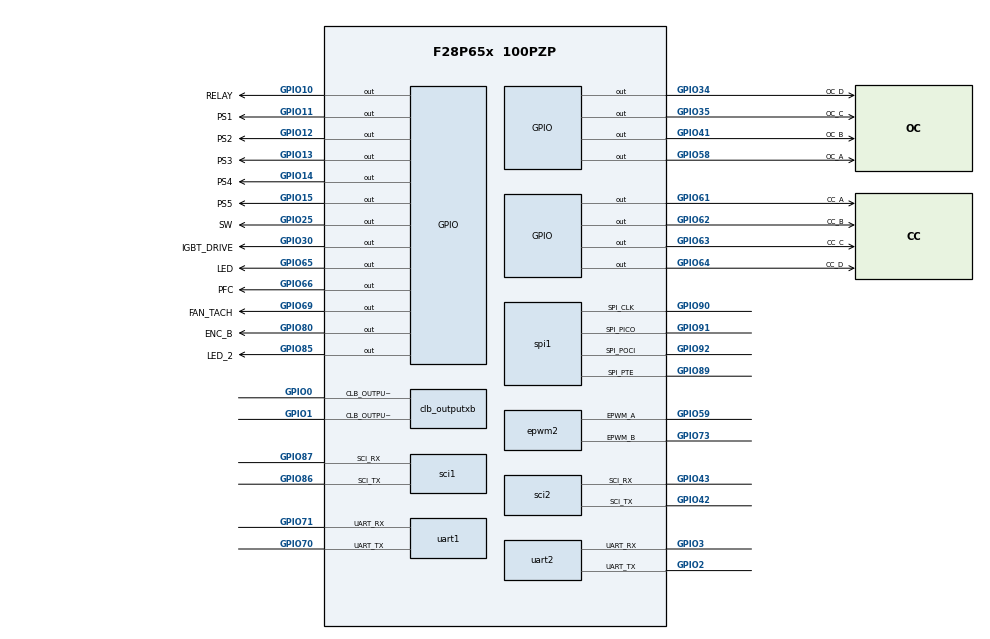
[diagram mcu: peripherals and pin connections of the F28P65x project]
/**
 * @cliArgs --device "F28P65x" --part "F28P65x_100PZP" --package "100PZP" --context "CPU1" --product "C2000WARE@6.00.01.00"
 * @versions {"tool":"1.26.0+4407"}
 */

/**
 * Import the modules used in this configuration.
 */
const adc              = scripting.addModule("/driverlib/adc.js", {}, false);
const adc1             = adc.addInstance();
const adc2             = adc.addInstance();
const adc3             = adc.addInstance();
const asysctl          = scripting.addModule("/driverlib/asysctl.js");
const led              = scripting.addModule("/driverlib/board_components/led", {}, false);
const led1             = led.addInstance();
const led2             = led.addInstance();
const clb              = scripting.addModule("/driverlib/clb.js", {}, false);
const clb1             = clb.addInstance();
const clb_outputxbar   = scripting.addModule("/driverlib/clb_outputxbar.js", {}, false);
const clb_outputxbar1  = clb_outputxbar.addInstance();
const clb_outputxbar2  = clb_outputxbar.addInstance();
const clbxbar          = scripting.addModule("/driverlib/clbxbar.js", {}, false);
const clbxbar1         = clbxbar.addInstance();
const clbxbar2         = clbxbar.addInstance();
const clbxbar3         = clbxbar.addInstance();
const cputimer         = scripting.addModule("/driverlib/cputimer.js", {}, false);
const cputimer1        = cputimer.addInstance();
const dac              = scripting.addModule("/driverlib/dac.js", {}, false);
const dac1             = dac.addInstance();
const dac2             = dac.addInstance();
const epwm             = scripting.addModule("/driverlib/epwm.js", {}, false);
const epwm1            = epwm.addInstance();
const epwm2            = epwm.addInstance();
const epwm3            = epwm.addInstance();
const epwm4            = epwm.addInstance();
const gpio             = scripting.addModule("/driverlib/gpio.js", {}, false);
const gpio3            = gpio.addInstance();
const gpio4            = gpio.addInstance();
const gpio5            = gpio.addInstance();
const gpio6            = gpio.addInstance();
const gpio7            = gpio.addInstance();
const gpio8            = gpio.addInstance();
const gpio9            = gpio.addInstance();
const gpio10           = gpio.addInstance();
const gpio11           = gpio.addInstance();
const gpio12           = gpio.addInstance();
const gpio13           = gpio.addInstance();
const gpio14           = gpio.addInstance();
const gpio15           = gpio.addInstance();
const gpio16           = gpio.addInstance();
const gpio17           = gpio.addInstance();
const gpio18           = gpio.addInstance();
const gpio19           = gpio.addInstance();
const gpio20           = gpio.addInstance();
const gpio21           = gpio.addInstance();
const gpio22           = gpio.addInstance();
const inputxbar_input  = scripting.addModule("/driverlib/inputxbar_input.js", {}, false);
const inputxbar_input1 = inputxbar_input.addInstance();
const inputxbar_input2 = inputxbar_input.addInstance();
const inputxbar_input3 = inputxbar_input.addInstance();
const inputxbar_input4 = inputxbar_input.addInstance();
const inputxbar_input5 = inputxbar_input.addInstance();
const sci              = scripting.addModule("/driverlib/sci.js", {}, false);
const sci1             = sci.addInstance();
const sci2             = sci.addInstance();
const spi              = scripting.addModule("/driverlib/spi.js", {}, false);
const spi1             = spi.addInstance();
const uart             = scripting.addModule("/driverlib/uart.js", {}, false);
const uart1            = uart.addInstance();
const uart2            = uart.addInstance();
const TILE             = scripting.addModule("/utilities/clb_tool/clb_syscfg/source/TILE", {}, false);
const TILE1            = TILE.addInstance();

/**
 * Write custom configuration values to the imported modules.
 */
adc1.$name               = "myADC0";
adc1.soc0Channel         = "ADC_CH_ADCIN1";
adc1.soc1Channel         = "ADC_CH_ADCIN2";
adc1.soc2Channel         = "ADC_CH_ADCIN3";
adc1.soc3Channel         = "ADC_CH_ADCIN4";
adc1.soc4Channel         = "ADC_CH_ADCIN5";
adc1.enabledSOCs         = ["ADC_SOC_NUMBER0","ADC_SOC_NUMBER1","ADC_SOC_NUMBER2","ADC_SOC_NUMBER3","ADC_SOC_NUMBER4","ADC_SOC_NUMBER5","ADC_SOC_NUMBER6","ADC_SOC_NUMBER7"];
adc1.soc5Channel         = "ADC_CH_ADCIN6";
adc1.soc6Channel         = "ADC_CH_ADCIN10";
adc1.soc7Channel         = "ADC_CH_ADCIN11";
adc1.enableInterrupt1    = true;
adc1.interrupt1SOCSource = "ADC_INT_TRIGGER_EOC3";
adc1.registerInterrupts  = ["1"];
adc1.soc0SampleWindow    = 20;
adc1.soc1SampleWindow    = 20;
adc1.soc2SampleWindow    = 20;
adc1.soc3SampleWindow    = 20;
adc1.soc4SampleWindow    = 20;
adc1.soc5SampleWindow    = 20;
adc1.soc6SampleWindow    = 20;
adc1.soc7SampleWindow    = 20;
adc1.adcClockPrescaler   = "ADC_CLK_DIV_6_0";
adc1.useInterrupts       = false;

adc2.$name               = "myADC1";
adc2.adcBase             = "ADCB_BASE";
adc2.soc1Channel         = "ADC_CH_ADCIN2";
adc2.soc2Channel         = "ADC_CH_ADCIN3";
adc2.soc3Channel         = "ADC_CH_ADCIN6";
adc2.soc4Channel         = "ADC_CH_ADCIN7";
adc2.enabledInts         = ["ADC_INT_NUMBER1"];
adc2.interrupt1SOCSource = "ADC_INT_TRIGGER_EOC5";
adc2.enableInterrupt1    = true;
adc2.soc0SampleWindow    = 20;
adc2.soc1SampleWindow    = 20;
adc2.soc2SampleWindow    = 20;
adc2.soc3SampleWindow    = 20;
adc2.soc4SampleWindow    = 20;
adc2.adcClockPrescaler   = "ADC_CLK_DIV_6_0";
adc2.enabledSOCs         = ["ADC_SOC_NUMBER0","ADC_SOC_NUMBER1","ADC_SOC_NUMBER2","ADC_SOC_NUMBER3","ADC_SOC_NUMBER4","ADC_SOC_NUMBER5"];
adc2.soc5Channel         = "ADC_CH_ADCIN6";
adc2.soc5SampleWindow    = 20;
adc2.useInterrupts       = false;

adc3.$name             = "myADC2";
adc3.adcClockPrescaler = "ADC_CLK_DIV_4_0";
adc3.adcResolutionMode = "ADC_RESOLUTION_16BIT";
adc3.adcSignalMode     = "ADC_MODE_DIFFERENTIAL";
adc3.enabledSOCs       = ["ADC_SOC_NUMBER0","ADC_SOC_NUMBER1","ADC_SOC_NUMBER2","ADC_SOC_NUMBER3"];
adc3.soc0Channel       = "ADC_CH_ADCIN0_ADCIN1";
adc3.soc0SampleWindow  = 65;
adc3.soc1Channel       = "ADC_CH_ADCIN2_ADCIN3";
adc3.soc1SampleWindow  = 65;
adc3.soc2Channel       = "ADC_CH_ADCIN4_ADCIN5";
adc3.soc2SampleWindow  = 65;
adc3.soc3Channel       = "ADC_CH_ADCIN14_ADCIN15";
adc3.soc3SampleWindow  = 65;
adc3.adcBase           = "ADCC_BASE";

led1.$name                = "LED";
led1.gpio.gpioPin.$assign = "GPIO65";

led2.$name                = "LED_2";
led2.gpio.gpioPin.$assign = "GPIO85";

clb1.$name               = "myCLB0";
clb1.enableCLB           = true;
clb1.inputTypeCLB_IN0    = "GLOBAL";
clb1.attachTile          = true;
clb1.synchronizeCLB_IN0  = true;
clb1.inputTypeCLB_IN1    = "GLOBAL";
clb1.synchronizeCLB_IN1  = true;
clb1.inputTypeCLB_IN2    = "GLOBAL";
clb1.globalConfigCLB_IN2 = "CLB_GLOBAL_IN_MUX_CLB_AUXSIG2";
clb1.synchronizeCLB_IN2  = true;
clb1.initTile            = true;
clb1.inputsUsed          = ["CLB_IN0","CLB_IN1","CLB_IN2","CLB_IN3","CLB_IN4","CLB_IN5","CLB_IN6","CLB_IN7"];
clb1.globalConfigCLB_IN1 = "CLB_GLOBAL_IN_MUX_EPWM1B";
clb1.synchronizeCLB_IN3  = true;

clb_outputxbar1.$name                                    = "myCLB_OUTPUTXBAR0";
clb_outputxbar1.muxesUsed                                = ["XBAR_MUX00"];
clb_outputxbar1.clb_outputxbar.$assign                   = "CLB_OUTPUTXBAR1";
clb_outputxbar1.clb_outputxbar.clb_outputxbarPin.$assign = "GPIO0";

clb_outputxbar2.$name                                    = "myCLB_OUTPUTXBAR1";
clb_outputxbar2.muxesUsed                                = ["XBAR_MUX01"];
clb_outputxbar2.clb_outputxbar.$assign                   = "CLB_OUTPUTXBAR2";
clb_outputxbar2.clb_outputxbar.clb_outputxbarPin.$assign = "GPIO1";

clbxbar1.$name           = "myCLBXBAR0";
clbxbar1.mux1Config      = "XBAR_CLB_MUX01_INPUTXBAR1_INPUT1";
clbxbar1.mux3Config      = "XBAR_CLB_MUX03_INPUTXBAR1_INPUT2";
clbxbar1.mux9Config      = "XBAR_CLB_MUX09_INPUTXBAR1_INPUT5";
clbxbar1.mux11Config     = "XBAR_CLB_MUX11_INPUTXBAR1_INPUT6";
clbxbar1.sourceSignals   = ["INPUTXBAR1_INPUT4"];
clbxbar1.useSourceSelect = true;

clbxbar2.$name           = "myCLBXBAR1";
clbxbar2.useSourceSelect = true;
clbxbar2.sourceSignals   = ["INPUTXBAR1_INPUT5"];
clbxbar2.auxInput        = "XBAR_AUXSIG1";

clbxbar3.$name           = "myCLBXBAR2";
clbxbar3.auxInput        = "XBAR_AUXSIG2";
clbxbar3.useSourceSelect = true;
clbxbar3.sourceSignals   = ["INPUTXBAR1_INPUT6"];

const divider4       = system.clockTree["CLBCLKDIV"];
divider4.divideValue = 1;

const divider8       = system.clockTree["EPWMCLKDIV"];
divider8.divideValue = 1;

cputimer1.$name                    = "myCPUTIMER0";
cputimer1.timerPeriod              = 600000000;
cputimer1.enableInterrupt          = true;
cputimer1.registerInterrupts       = true;
cputimer1.startTimer               = true;
cputimer1.timerInt.enableInterrupt = true;

dac1.$name            = "myDAC0";
dac1.enableOutput     = true;
dac1.referenceVoltage = "DAC_REF_ADC_VREFHI";

dac2.$name            = "myDAC1";
dac2.dacBase          = "DACC_BASE";
dac2.enableOutput     = true;
dac2.referenceVoltage = "DAC_REF_ADC_VREFHI";

const analog  = scripting.addModule("/driverlib/analog.js", {}, false);
const analog1 = analog.addInstance({}, false);
analog1.$name = "myANALOGPinMux0";
adc1.analog   = analog1;
adc2.analog   = analog1;
adc3.analog   = analog1;
dac1.analog   = analog1;
dac2.analog   = analog1;

epwm1.epwmTimebase_hsClockDiv                                  = "EPWM_HSCLOCK_DIVIDER_1";
epwm1.epwmTimebase_counterMode                                 = "EPWM_COUNTER_MODE_UP";
epwm1.epwmTimebase_period                                      = 10000;
epwm1.epwmCounterCompare_cmpA                                  = 5000;
epwm1.epwmActionQualifier_EPWM_AQ_OUTPUT_A_ON_TIMEBASE_ZERO    = "EPWM_AQ_OUTPUT_HIGH";
epwm1.epwmActionQualifier_EPWM_AQ_OUTPUT_A_ON_TIMEBASE_UP_CMPA = "EPWM_AQ_OUTPUT_LOW";
epwm1.epwmActionQualifier_EPWM_AQ_OUTPUT_B_ON_TIMEBASE_ZERO    = "EPWM_AQ_OUTPUT_HIGH";
epwm1.epwmActionQualifier_EPWM_AQ_OUTPUT_B_ON_TIMEBASE_UP_CMPB = "EPWM_AQ_OUTPUT_LOW";
epwm1.epwmCounterCompare_cmpB                                  = 5000;
epwm1.$name                                                    = "PWM1";
epwm1.useCase                                                  = "CUSTOM";
epwm1.epwm.$assign                                             = "EPWM1";

epwm2.copyFrom                                                 = "myEPWM0";
epwm2.epwmTimebase_hsClockDiv                                  = "EPWM_HSCLOCK_DIVIDER_1";
epwm2.epwmTimebase_period                                      = 10000;
epwm2.epwmTimebase_counterMode                                 = "EPWM_COUNTER_MODE_UP";
epwm2.epwmCounterCompare_cmpA                                  = 5000;
epwm2.epwmCounterCompare_cmpB                                  = 5000;
epwm2.epwmActionQualifier_EPWM_AQ_OUTPUT_A_ON_TIMEBASE_ZERO    = "EPWM_AQ_OUTPUT_HIGH";
epwm2.epwmActionQualifier_EPWM_AQ_OUTPUT_A_ON_TIMEBASE_UP_CMPA = "EPWM_AQ_OUTPUT_LOW";
epwm2.epwmActionQualifier_EPWM_AQ_OUTPUT_B_ON_TIMEBASE_ZERO    = "EPWM_AQ_OUTPUT_HIGH";
epwm2.epwmActionQualifier_EPWM_AQ_OUTPUT_B_ON_TIMEBASE_UP_CMPB = "EPWM_AQ_OUTPUT_LOW";
epwm2.$name                                                    = "PWM2";
epwm2.epwm.$assign                                             = "EPWM5";
epwm2.epwm.epwm_aPin.$assign                                   = "GPIO59";
epwm2.epwm.epwm_bPin.$assign                                   = "GPIO73";

epwm3.copyFrom                                                 = "myEPWM1";
epwm3.epwmTimebase_hsClockDiv                                  = "EPWM_HSCLOCK_DIVIDER_1";
epwm3.epwmTimebase_period                                      = 10000;
epwm3.epwmTimebase_counterMode                                 = "EPWM_COUNTER_MODE_UP";
epwm3.epwmCounterCompare_cmpA                                  = 5000;
epwm3.epwmCounterCompare_cmpB                                  = 5000;
epwm3.epwmActionQualifier_EPWM_AQ_OUTPUT_A_ON_TIMEBASE_ZERO    = "EPWM_AQ_OUTPUT_HIGH";
epwm3.epwmActionQualifier_EPWM_AQ_OUTPUT_A_ON_TIMEBASE_UP_CMPA = "EPWM_AQ_OUTPUT_LOW";
epwm3.epwmActionQualifier_EPWM_AQ_OUTPUT_B_ON_TIMEBASE_ZERO    = "EPWM_AQ_OUTPUT_HIGH";
epwm3.epwmActionQualifier_EPWM_AQ_OUTPUT_B_ON_TIMEBASE_UP_CMPB = "EPWM_AQ_OUTPUT_LOW";
epwm3.$name                                                    = "PWM3";
epwm3.epwm.$assign                                             = "EPWM3";

epwm4.copyFrom                                                 = "myEPWM1";
epwm4.epwmTimebase_hsClockDiv                                  = "EPWM_HSCLOCK_DIVIDER_1";
epwm4.epwmTimebase_period                                      = 10000;
epwm4.epwmTimebase_counterMode                                 = "EPWM_COUNTER_MODE_UP";
epwm4.epwmCounterCompare_cmpA                                  = 5000;
epwm4.epwmCounterCompare_cmpB                                  = 5000;
epwm4.epwmActionQualifier_EPWM_AQ_OUTPUT_A_ON_TIMEBASE_ZERO    = "EPWM_AQ_OUTPUT_HIGH";
epwm4.epwmActionQualifier_EPWM_AQ_OUTPUT_A_ON_TIMEBASE_UP_CMPA = "EPWM_AQ_OUTPUT_LOW";
epwm4.epwmActionQualifier_EPWM_AQ_OUTPUT_B_ON_TIMEBASE_ZERO    = "EPWM_AQ_OUTPUT_HIGH";
epwm4.epwmActionQualifier_EPWM_AQ_OUTPUT_B_ON_TIMEBASE_UP_CMPB = "EPWM_AQ_OUTPUT_LOW";
epwm4.$name                                                    = "PWM4";

gpio3.$name                     = "PS1";
gpio3.padConfig                 = "PULLUP";
gpio3.qualMode                  = "GPIO_QUAL_ASYNC";
gpio3.useInterrupt              = true;
gpio3.initialValue              = 1;
gpio3.gpioPin.$assign           = "GPIO11";
gpio3.xint.enableInt            = true;
gpio3.xint.registerInterrupts   = true;
gpio3.xint.xInt.enableInterrupt = true;

gpio4.$name                     = "PS3";
gpio4.padConfig                 = "PULLUP";
gpio4.useInterrupt              = true;
gpio4.qualMode                  = "GPIO_QUAL_ASYNC";
gpio4.initialValue              = 1;
gpio4.gpioPin.$assign           = "GPIO13";
gpio4.xint.xintNum              = "GPIO_INT_XINT3";
gpio4.xint.enableInt            = true;
gpio4.xint.registerInterrupts   = true;
gpio4.xint.intType              = "GPIO_INT_TYPE_RISING_EDGE";
gpio4.xint.xInt.enableInterrupt = true;

gpio5.$name                     = "PS4";
gpio5.padConfig                 = "PULLUP";
gpio5.useInterrupt              = true;
gpio5.qualMode                  = "GPIO_QUAL_ASYNC";
gpio5.gpioPin.$assign           = "GPIO14";
gpio5.xint.xintNum              = "GPIO_INT_XINT4";
gpio5.xint.enableInt            = true;
gpio5.xint.registerInterrupts   = true;
gpio5.xint.xInt.enableInterrupt = true;

gpio6.$name                     = "PS5";
gpio6.padConfig                 = "PULLUP";
gpio6.useInterrupt              = true;
gpio6.qualMode                  = "GPIO_QUAL_ASYNC";
gpio6.gpioPin.$assign           = "GPIO15";
gpio6.xint.xintNum              = "GPIO_INT_XINT5";
gpio6.xint.enableInt            = true;
gpio6.xint.registerInterrupts   = true;
gpio6.xint.xInt.enableInterrupt = true;

gpio7.padConfig       = "PULLUP";
gpio7.qualMode        = "GPIO_QUAL_ASYNC";
gpio7.$name           = "OC_A";
gpio7.gpioPin.$assign = "GPIO58";

gpio8.padConfig       = "PULLUP";
gpio8.qualMode        = "GPIO_QUAL_ASYNC";
gpio8.$name           = "OC_B";
gpio8.gpioPin.$assign = "GPIO41";

gpio9.padConfig       = "PULLUP";
gpio9.$name           = "CC_A";
gpio9.gpioPin.$assign = "GPIO61";

gpio10.padConfig       = "PULLUP";
gpio10.$name           = "CC_B";
gpio10.gpioPin.$assign = "GPIO62";

gpio11.padConfig       = "PULLUP";
gpio11.$name           = "CC_C";
gpio11.gpioPin.$assign = "GPIO63";

gpio12.padConfig       = "PULLUP";
gpio12.$name           = "CC_D";
gpio12.gpioPin.$assign = "GPIO64";

gpio13.$name             = "RELAY";
gpio13.writeInitialValue = true;
gpio13.direction         = "GPIO_DIR_MODE_OUT";
gpio13.gpioPin.$assign   = "GPIO10";

gpio14.$name           = "PFC";
gpio14.direction       = "GPIO_DIR_MODE_OUT";
gpio14.gpioPin.$assign = "GPIO66";

gpio15.$name           = "SW";
gpio15.gpioPin.$assign = "GPIO25";

gpio16.$name           = "ENC_B";
gpio16.gpioPin.$assign = "GPIO80";

gpio17.$name = "ENC_A";

gpio18.$name           = "FAN_TACH";
gpio18.gpioPin.$assign = "GPIO69";

gpio19.padConfig       = "PULLUP";
gpio19.qualMode        = "GPIO_QUAL_ASYNC";
gpio19.$name           = "OC_C";
gpio19.gpioPin.$assign = "GPIO35";

gpio20.padConfig       = "PULLUP";
gpio20.qualMode        = "GPIO_QUAL_ASYNC";
gpio20.$name           = "OC_D";
gpio20.gpioPin.$assign = "GPIO34";

gpio21.$name                     = "PS2";
gpio21.padConfig                 = "PULLUP";
gpio21.qualMode                  = "GPIO_QUAL_ASYNC";
gpio21.useInterrupt              = true;
gpio21.initialValue              = 1;
gpio21.gpioPin.$assign           = "GPIO12";
gpio21.xint.xintNum              = "GPIO_INT_XINT2";
gpio21.xint.enableInt            = true;
gpio21.xint.registerInterrupts   = true;
gpio21.xint.xInt.enableInterrupt = true;

gpio22.$name           = "IGBT_DRIVE";
gpio22.gpioPin.$assign = "GPIO30";

inputxbar_input1.$name          = "myINPUTXBARINPUT0";
inputxbar_input1.inputxbarInput = "XBAR_INPUT4";
inputxbar_input1.inputxbarGpio  = "GPIO11";
gpio3.xint.inputxbar            = inputxbar_input1;

inputxbar_input2.$name          = "myINPUTXBARINPUT1";
inputxbar_input2.inputxbarInput = "XBAR_INPUT5";
inputxbar_input2.inputxbarGpio  = "GPIO12";
gpio21.xint.inputxbar           = inputxbar_input2;

inputxbar_input3.$name          = "myINPUTXBARINPUT2";
inputxbar_input3.inputxbarInput = "XBAR_INPUT6";
inputxbar_input3.inputxbarGpio  = "GPIO13";
gpio4.xint.inputxbar            = inputxbar_input3;

inputxbar_input4.$name          = "myINPUTXBARINPUT3";
inputxbar_input4.inputxbarInput = "XBAR_INPUT13";
gpio5.xint.inputxbar            = inputxbar_input4;
inputxbar_input4.inputxbarGpio  = "GPIO14";

inputxbar_input5.$name          = "myINPUTXBARINPUT4";
inputxbar_input5.inputxbarInput = "XBAR_INPUT14";
gpio6.xint.inputxbar            = inputxbar_input5;
inputxbar_input5.inputxbarGpio  = "GPIO15";

sci1.$name                 = "mySCI0";
sci1.sci.$assign           = "SCIB";
sci1.sci.sci_rxPin.$assign = "GPIO87";
sci1.sci.sci_txPin.$assign = "GPIO86";
sci1.rxQual.$name          = "myGPIOQUAL4";
sci1.txQual.$name          = "myGPIOQUAL5";

sci2.$name                 = "mySCI1";
sci2.rxFifo                = "SCI_FIFO_RX1";
sci2.sci.$assign           = "SCIA";
sci2.sci.sci_rxPin.$assign = "GPIO43";
sci2.sci.sci_txPin.$assign = "GPIO42";
sci2.rxQual.$name          = "myGPIOQUAL6";
sci2.txQual.$name          = "myGPIOQUAL7";

spi1.$name                   = "mySPI0";
spi1.spi.spi_picoPin.$assign = "GPIO91";
spi1.spi.spi_pociPin.$assign = "GPIO92";
spi1.spi.spi_clkPin.$assign  = "GPIO90";
spi1.spi.spi_ptePin.$assign  = "GPIO89";
spi1.picoQual.$name          = "myGPIOQUAL8";
spi1.pociQual.$name          = "myGPIOQUAL9";
spi1.clkQual.$name           = "myGPIOQUAL10";
spi1.pteQual.$name           = "myGPIOQUAL11";

uart1.$name                   = "myUART0";
uart1.uart.uart_txPin.$assign = "GPIO70";
uart1.uart.uart_rxPin.$assign = "GPIO71";
uart1.txQual.$name            = "myGPIOQUAL0";
uart1.rxQual.$name            = "myGPIOQUAL1";

uart2.$name                   = "myUART1";
uart2.uart.uart_txPin.$assign = "GPIO2";
uart2.uart.uart_rxPin.$assign = "GPIO3";
uart2.txQual.$name            = "myGPIOQUAL2";
uart2.rxQual.$name            = "myGPIOQUAL3";

TILE1.$name                = "TILE0";
clb1.tile                  = TILE1;
TILE1.BOUNDARY.$name       = "BOUNDARY0";
TILE1.LUT_0.$name          = "LUT_0";
TILE1.LUT_0.eqn            = "i0";
TILE1.LUT_0.i0             = "BOUNDARY.in0";
TILE1.LUT_1.$name          = "LUT_1";
TILE1.LUT_1.eqn            = "i1";
TILE1.LUT_1.i1             = "BOUNDARY.in1";
TILE1.LUT_2.$name          = "LUT_2";
TILE1.FSM_0.$name          = "FSM_0";
TILE1.FSM_1.$name          = "FSM_1";
TILE1.FSM_2.$name          = "FSM_2";
TILE1.COUNTER_0.$name      = "COUNTER_0";
TILE1.COUNTER_0.match1_val = "";
TILE1.COUNTER_0.match2_val = "";
TILE1.COUNTER_1.$name      = "COUNTER_1";
TILE1.COUNTER_2.$name      = "COUNTER_2";
TILE1.OUTLUT_0.$name       = "OUTLUT_0";
TILE1.OUTLUT_0.eqn         = "!i0";
TILE1.OUTLUT_0.i0          = "LUT_0.OUT";
TILE1.OUTLUT_1.$name       = "OUTLUT_1";
TILE1.OUTLUT_1.eqn         = "i0";
TILE1.OUTLUT_1.i0          = "LUT_1.OUT";
TILE1.OUTLUT_2.$name       = "OUTLUT_2";
TILE1.OUTLUT_3.$name       = "OUTLUT_3";
TILE1.OUTLUT_4.$name       = "OUTLUT_4";
TILE1.OUTLUT_5.$name       = "OUTLUT_5";
TILE1.OUTLUT_6.$name       = "OUTLUT_6";
TILE1.OUTLUT_7.$name       = "OUTLUT_7";
TILE1.HLC.$name            = "HLC_0";
TILE1.HLC.program0.$name   = "HLCP_0";
TILE1.HLC.program1.$name   = "HLCP_1";
TILE1.HLC.program2.$name   = "HLCP_2";
TILE1.HLC.program3.$name   = "HLCP_3";
TILE1.AOC_0.$name          = "AOC_0";
TILE1.AOC_1.$name          = "AOC_1";
TILE1.AOC_2.$name          = "AOC_2";
TILE1.AOC_3.$name          = "AOC_3";
TILE1.AOC_4.$name          = "AOC_4";
TILE1.AOC_5.$name          = "AOC_5";
TILE1.AOC_6.$name          = "AOC_6";
TILE1.AOC_7.$name          = "AOC_7";

/**
 * Pinmux solution for unlocked pins/peripherals. This ensures that minor changes to the automatic solver in a future
 * version of the tool will not impact the pinmux you originally saw.  These lines can be completely deleted in order to
 * re-solve from scratch.
 */
analog1.analog.$suggestSolution                    = "ANALOG";
analog1.analog["a0/daca_outPin"].$suggestSolution  = "A0/DACA_OUT";
analog1.analog.a1Pin.$suggestSolution              = "A1";
analog1.analog["a10, gpio213Pin"].$suggestSolution = "A10, GPIO213";
analog1.analog["a11, gpio214Pin"].$suggestSolution = "A11, GPIO214";
analog1.analog["a14/b14/c14Pin"].$suggestSolution  = "A14/B14/C14";
analog1.analog["a15/b15/c15Pin"].$suggestSolution  = "A15/B15/C15";
analog1.analog.a2Pin.$suggestSolution              = "A2";
analog1.analog.a3Pin.$suggestSolution              = "A3";
analog1.analog.a4Pin.$suggestSolution              = "A4";
analog1.analog.a5Pin.$suggestSolution              = "A5";
analog1.analog["a6, gpio209Pin"].$suggestSolution  = "A6, GPIO209";
analog1.analog["b0/vdacPin"].$suggestSolution      = "B0/VDAC";
analog1.analog["b1/dacc_outPin"].$suggestSolution  = "B1/DACC_OUT";
analog1.analog.b2Pin.$suggestSolution              = "B2";
analog1.analog.b3Pin.$suggestSolution              = "B3";
analog1.analog["b6, gpio207Pin"].$suggestSolution  = "B6, GPIO207";
analog1.analog["b7, gpio208Pin"].$suggestSolution  = "B7, GPIO208";
analog1.analog["c0, gpio199Pin"].$suggestSolution  = "C0, GPIO199";
analog1.analog.c2Pin.$suggestSolution              = "C2";
analog1.analog["c3, gpio206Pin"].$suggestSolution  = "C3, GPIO206";
analog1.analog["c4, gpio205Pin"].$suggestSolution  = "C4, GPIO205";
analog1.analog["c5, gpio204Pin"].$suggestSolution  = "C5, GPIO204";
analog1.analog["c6, gpio203Pin"].$suggestSolution  = "C6, GPIO203";
analog1.analog["c1, gpio200Pin"].$suggestSolution  = "C1, GPIO200";
epwm3.epwm.epwm_aPin.$suggestSolution              = "GPIO4";
epwm3.epwm.epwm_bPin.$suggestSolution              = "GPIO60";
epwm4.epwm.$suggestSolution                        = "EPWM4";
epwm4.epwm.epwm_aPin.$suggestSolution              = "GPIO46";
epwm4.epwm.epwm_bPin.$suggestSolution              = "GPIO47";
gpio17.gpioPin.$suggestSolution                    = "GPIO100";
spi1.spi.$suggestSolution                          = "SPID";
uart1.uart.$suggestSolution                        = "UARTB";
uart2.uart.$suggestSolution                        = "UARTA";
